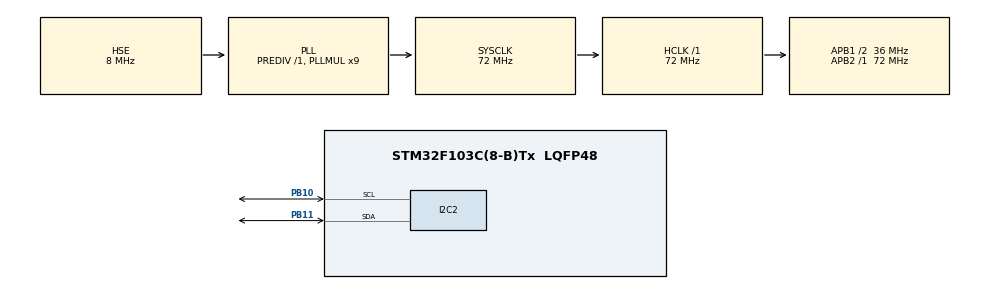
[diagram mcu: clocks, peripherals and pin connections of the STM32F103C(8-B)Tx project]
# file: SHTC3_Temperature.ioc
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Mcu.Family=STM32F1
Mcu.Name=STM32F103C(8-B)Tx
Mcu.Package=LQFP48
NVIC.PriorityGroup=NVIC_PRIORITYGROUP_4
PA13.Mode=Serial_Wire
PA13.Signal=SYS_JTMS-SWDIO
PA14.Mode=Serial_Wire
PA14.Signal=SYS_JTCK-SWCLK
PB10.Mode=I2C
PB10.Signal=I2C2_SCL
PB11.Mode=I2C
PB11.Signal=I2C2_SDA
PD0-OSC_IN.Mode=HSE-External-Oscillator
PD0-OSC_IN.Signal=RCC_OSC_IN
PD1-OSC_OUT.Mode=HSE-External-Oscillator
PD1-OSC_OUT.Signal=RCC_OSC_OUT
ProjectManager.HeapSize=0x200
ProjectManager.StackSize=0x400
ProjectManager.TargetToolchain=STM32CubeIDE
RCC.AHBFreq_Value=72000000
RCC.APB1CLKDivider=RCC_HCLK_DIV2
RCC.APB1Freq_Value=36000000
RCC.APB1TimFreq_Value=72000000
RCC.APB2Freq_Value=72000000
RCC.APB2TimFreq_Value=72000000
RCC.HCLKFreq_Value=72000000
RCC.PLLMUL=RCC_PLL_MUL9
RCC.PLLSourceVirtual=RCC_PLLSOURCE_HSE
RCC.SYSCLKFreq_VALUE=72000000
RCC.SYSCLKSource=RCC_SYSCLKSOURCE_PLLCLK
RCC.USBFreq_Value=72000000
board=custom

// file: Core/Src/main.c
/* USER CODE BEGIN Header */
/**
  ******************************************************************************
  * @file           : main.c
  * @brief          : Main program body
  ******************************************************************************
  * @attention
  *
  * Copyright (c) 2023 STMicroelectronics.
  * All rights reserved.
  *
  * This software is licensed under terms that can be found in the LICENSE file
  * in the root directory of this software component.
  * If no LICENSE file comes with this software, it is provided AS-IS.
  *
  ******************************************************************************
  */
/* USER CODE END Header */
#include "main.h"

I2C_HandleTypeDef hi2c2;

void SystemClock_Config(void);
static void MX_GPIO_Init(void);
static void MX_I2C2_Init(void);

/* USER CODE BEGIN 0 */

#define SHTC3_ADDR_REG 0x70
#define READ_ID 0xEFC8 // command: read ID register
#define SOFT_RESET 0x805D // soft reset
#define SLEEP 0xB098 // sleep
#define WAKEUP 0x3517 // wakeup
#define MEAS_T_RH_POLLING 0x7866 // meas. read T first, clock stretching disabled
#define MEAS_T_RH_CLOCKSTR 0x7CA2 // meas. read T first, clock stretching enabled
#define MEAS_RH_T_POLLING 0x58E0 // meas. read RH first, clock stretching disabled
#define MEAS_RH_T_CLOCKSTR 0x5C24  // meas. read RH first, clock stretching enabled

uint32_t checkReady;
uint32_t val;

void SHTC3_Init(void)
{
	uint8_t data[8];

	//data = 0x3517;
	//HAL_I2C_Mem_Write(&hi2c2, SHTC3_ADDR_REG, WAKEUP, 1, &data, 1, 10000);
	//HAL_I2C_Mem_Read(&hi2c2, SHTC3_ADDR_REG, READ_ID, 1, &check, 1, 10000);
	HAL_I2C_Master_Receive(&hi2c2, SHTC3_ADDR_REG, MEAS_RH_T_POLLING, 4, HAL_MAX_DELAY);

	data

//	checkReady = HAL_I2C_IsDeviceReady(&hi2c2, SHTC3_ADDR_REG, 100, HAL_MAX_DELAY);
//
//	if (checkReady == HAL_OK) {
//
//	}

}

/* USER CODE END 0 */

int main(void)
{

  /* MCU Configuration--------------------------------------------------------*/

  /* Reset of all peripherals, Initializes the Flash interface and the Systick. */
  HAL_Init();

  /* Configure the system clock */
  SystemClock_Config();

  /* Initialize all configured peripherals */
  MX_GPIO_Init();
  MX_I2C2_Init();
  /* USER CODE BEGIN 2 */

  SHTC3_Init();

  /* USER CODE END 2 */

  /* Infinite loop */
  while (1)
  {

  }
}

void SystemClock_Config(void)
{
  RCC_OscInitTypeDef RCC_OscInitStruct = {0};
  RCC_ClkInitTypeDef RCC_ClkInitStruct = {0};

  /** Initializes the RCC Oscillators according to the specified parameters
  * in the RCC_OscInitTypeDef structure.
  */
  RCC_OscInitStruct.OscillatorType = RCC_OSCILLATORTYPE_HSE;
  RCC_OscInitStruct.HSEState = RCC_HSE_ON;
  RCC_OscInitStruct.HSEPredivValue = RCC_HSE_PREDIV_DIV1;
  RCC_OscInitStruct.HSIState = RCC_HSI_ON;
  RCC_OscInitStruct.PLL.PLLState = RCC_PLL_ON;
  RCC_OscInitStruct.PLL.PLLSource = RCC_PLLSOURCE_HSE;
  RCC_OscInitStruct.PLL.PLLMUL = RCC_PLL_MUL9;
  if (HAL_RCC_OscConfig(&RCC_OscInitStruct) != HAL_OK)
  {
    Error_Handler();
  }

  /** Initializes the CPU, AHB and APB buses clocks
  */
  RCC_ClkInitStruct.ClockType = RCC_CLOCKTYPE_HCLK|RCC_CLOCKTYPE_SYSCLK
                              |RCC_CLOCKTYPE_PCLK1|RCC_CLOCKTYPE_PCLK2;
  RCC_ClkInitStruct.SYSCLKSource = RCC_SYSCLKSOURCE_PLLCLK;
  RCC_ClkInitStruct.AHBCLKDivider = RCC_SYSCLK_DIV1;
  RCC_ClkInitStruct.APB1CLKDivider = RCC_HCLK_DIV2;
  RCC_ClkInitStruct.APB2CLKDivider = RCC_HCLK_DIV1;

  if (HAL_RCC_ClockConfig(&RCC_ClkInitStruct, FLASH_LATENCY_2) != HAL_OK)
  {
    Error_Handler();
  }
}

static void MX_I2C2_Init(void)
{

  hi2c2.Instance = I2C2;
  hi2c2.Init.ClockSpeed = 100000;
  hi2c2.Init.DutyCycle = I2C_DUTYCYCLE_2;
  hi2c2.Init.OwnAddress1 = 0;
  hi2c2.Init.AddressingMode = I2C_ADDRESSINGMODE_7BIT;
  hi2c2.Init.DualAddressMode = I2C_DUALADDRESS_DISABLE;
  hi2c2.Init.OwnAddress2 = 0;
  hi2c2.Init.GeneralCallMode = I2C_GENERALCALL_DISABLE;
  hi2c2.Init.NoStretchMode = I2C_NOSTRETCH_DISABLE;
  if (HAL_I2C_Init(&hi2c2) != HAL_OK)
  {
    Error_Handler();
  }

}

static void MX_GPIO_Init(void)
{

  /* GPIO Ports Clock Enable */
  __HAL_RCC_GPIOD_CLK_ENABLE();
  __HAL_RCC_GPIOB_CLK_ENABLE();
  __HAL_RCC_GPIOA_CLK_ENABLE();

}

void Error_Handler(void)
{
  __disable_irq();
  while (1)
  {
  }
}
